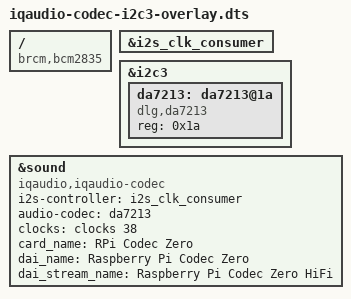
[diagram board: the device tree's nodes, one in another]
/dts-v1/;
/plugin/;

/ {
    compatible = "brcm,bcm2835";

    fragment@0 {
        target = <&i2s_clk_consumer>;
        __overlay__ {
            status = "okay";
        };
    };

    fragment@1 {
        target = <&i2c3>;
        __overlay__ {
            #address-cells = <1>;
            #size-cells = <0>;
            status = "okay";

            da7213: da7213@1a {
                #sound-dai-cells = <0>;
                compatible = "dlg,da7213";
                reg = <0x1a>;
                status = "okay";
            };
        };
    };

    fragment@2 {
        target = <&sound>;
        iqaudio_dac: __overlay__ {
            compatible = "iqaudio,iqaudio-codec";
            i2s-controller = <&i2s_clk_consumer>;
            audio-codec = <&da7213>;
            clocks = <&clocks 38>;
            status = "okay";
            card_name = "RPi Codec Zero";
            dai_name = "Raspberry Pi Codec Zero";
            dai_stream_name = "Raspberry Pi Codec Zero HiFi";
        };
    };
};

